# MKL28T7_CORE0 register map
Vendor: Freescale Semiconductor, Inc.; Series: Kinetis_L; File version: 1.6
CPU: CM0PLUS r0p0, little endian, no MPU, no FPU, VTOR, 2 interrupt priority bits
Registers are 32-bit, read-write, reset 0x0 unless marked. A register's access mark holds for its fields unless they carry their own. Offsets are from the block's base; [hi:lo] are bit positions; {n}, {i} and the like mark numbered series.

## CMP0 — High-Speed Comparator (CMP), Voltage Reference (VREF) Digital-to-Analog Converter (DAC), and Analog Mux (ANMUX)
Base 0x4006E000; register names take the prefix CMP0_
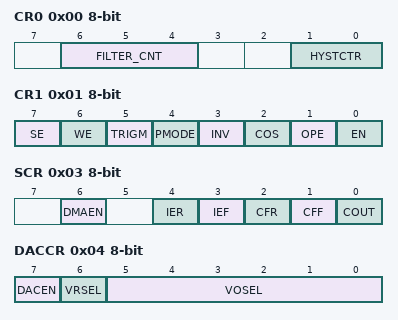
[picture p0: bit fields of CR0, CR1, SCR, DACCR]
0x00 CR0 8-bit — CMP Control Register 0
  [6:4] FILTER_CNT — Filter Sample Count
    0=Filter is disabled. If SE = 1, then COUT is a logic 0. This is not a legal state, and is not recommended. If SE = 0, COUT = COUTA.; 1=One sample must agree. The comparator output is simply sampled.; {v}={v} consecutive samples must agree (v=2..7)
  [1:0] HYSTCTR — Comparator hard block hysteresis control
    {v}=Level {v} (v=0..3)
0x01 CR1 8-bit — CMP Control Register 1
  [7] SE — Sample Enable
    0=Sampling mode is not selected; 1=Sampling mode is selected
  [6] WE — Windowing Enable
    0=Windowing mode is not selected; 1=Windowing mode is selected
  [5] TRIGM — Trigger Mode Enable
    0=Trigger mode is disabled; 1=Trigger mode is enabled
  [4] PMODE — Power Mode Select
    0=Low-Speed (LS) Comparison mode selected. In this mode, CMP has slower output propagation delay and lower current consumption.; 1=High-Speed (HS) Comparison mode selected. In this mode, CMP has faster output propagation delay and higher current consumption.
  [3] INV — Comparator INVERT
    0=Does not invert the comparator output; 1=Inverts the comparator output
  [2] COS — Comparator Output Select
    0=Set the filtered comparator output (CMPO) to equal COUT; 1=Set the unfiltered comparator output (CMPO) to equal COUTA
  [1] OPE — Comparator Output Pin Enable
    0=CMPO is not available on the associated CMPO output pin. If the comparator does not own the pin, this field has no effect.; 1=CMPO is available on the associated CMPO output pin. The comparator output (CMPO) is driven out on the associated CMPO output pin if the comparator owns the pin. If the comparator does not own the field, this bit has no effect.
  [0] EN — Comparator Module Enable
    0=Analog Comparator is disabled; 1=Analog Comparator is enabled
0x02 FPR 8-bit — CMP Filter Period Register
  [7:0] FILT_PER — Filter Sample Period
0x03 SCR 8-bit — CMP Status and Control Register
  [6] DMAEN — DMA Enable Control
    0=DMA is disabled; 1=DMA is enabled
  [4] IER — Comparator Interrupt Enable Rising
    0=Interrupt is disabled; 1=Interrupt is enabled
  [3] IEF — Comparator Interrupt Enable Falling
    0=Interrupt is disabled; 1=Interrupt is enabled
  [2] CFR — Analog Comparator Flag Rising
    0=Rising-edge on COUT has not been detected; 1=Rising-edge on COUT has occurred
  [1] CFF — Analog Comparator Flag Falling
    0=Falling-edge on COUT has not been detected; 1=Falling-edge on COUT has occurred
  [0] COUT ro — Analog Comparator Output
0x04 DACCR 8-bit — DAC Control Register
  [7] DACEN — DAC Enable
    0=DAC is disabled; 1=DAC is enabled
  [6] VRSEL — Supply Voltage Reference Source Select
    0=Vin1 is selected as resistor ladder network supply reference; 1=Vin2 is selected as resistor ladder network supply reference
  [5:0] VOSEL — DAC Output Voltage Select
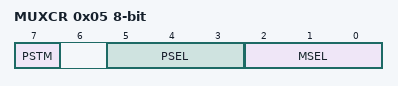
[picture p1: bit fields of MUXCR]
0x05 MUXCR 8-bit — MUX Control Register
  [7] PSTM — Pass Through Mode Enable
    0=Pass Through Mode is disabled; 1=Pass Through Mode is enabled
  [5:3] PSEL — Plus Input Mux Control
    {v}=IN{v} (v=0..7)
  [2:0] MSEL — Minus Input Mux Control
    {v}=IN{v} (v=0..7)

## CMP1 — High-Speed Comparator (CMP), Voltage Reference (VREF) Digital-to-Analog Converter (DAC), and Analog Mux (ANMUX)
Base 0x400EF000; register names take the prefix CMP1_
Registers as CMP0.

## VREF — Voltage Reference
Base 0x40072000; register names take the prefix VREF_
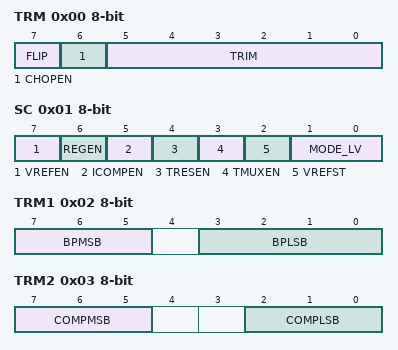
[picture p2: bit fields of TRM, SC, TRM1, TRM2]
0x00 TRM 8-bit (reset mask 0xC0) — VREF Trim Register
  [7] FLIP — Reverses the amplifier polarity
  [6] CHOPEN — Chop oscillator enable. When set, the internal chopping operation is enabled and the internal analog offset will be minimized.
    0=Chop oscillator is disabled; 1=Chop oscillator is enabled
  [5:0] TRIM — Trim bits
    0=Min; 63=Max
0x01 SC 8-bit — VREF Status and Control Register
  [7] VREFEN — Internal Voltage Reference enable
    0=The module is disabled; 1=The module is enabled
  [6] REGEN — Regulator enable
    0=Internal 1.75 V regulator is disabled; 1=Internal 1.75 V regulator is enabled
  [5] ICOMPEN — Second order curvature compensation enable
    0=Disabled; 1=Enabled
  [4] TRESEN — Test second order curvature compensation enable
    0=Disabled; 1=Enabled
  [3] TMUXEN — Test MUX enable
    0=Disabled; 1=Enabled
  [2] VREFST ro — Internal Voltage Reference stable
    0=The module is disabled or not stable; 1=The module is stable
  [1:0] MODE_LV — Buffer Mode selection
    0=Bandgap on only, for stabilization and startup; 1=High power buffer mode enabled; 2=Low-power buffer mode enabled
0x02 TRM1 8-bit — VREF Trim Register 1
  [7:5] BPMSB — BPMSB bits are used for thin trimming bandgap temperature curvature
  [3:0] BPLSB — BPLSB bits are used for thin trimming bandgap temperature curvature
0x03 TRM2 8-bit — VREF Trim Register 2
  [7:5] COMPMSB — COMPMSB bits are used for trimming the curvature used for the second-order temperature compensation
  [2:0] COMPLSB — COMPLSB bits are used for trimming the curvature used for the second-order temperature compensation
0x04 TRM3 8-bit — VREF Trim Register 3
  [3:0] CHOPOSCTRM — CHOPOSCTRM bits trim the chop oscillator clock
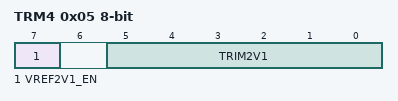
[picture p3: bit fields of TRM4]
0x05 TRM4 8-bit — VREF Trim Register 4
  [7] VREF2V1_EN — Internal Voltage Reference (2.1V) Enable
    0=VREF 2.1V is disabled; 1=VREF 2.1V is enabled
  [5:0] TRIM2V1 — VREF 2.1V Trim Bits
